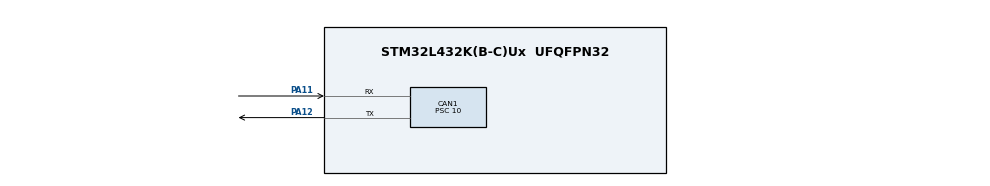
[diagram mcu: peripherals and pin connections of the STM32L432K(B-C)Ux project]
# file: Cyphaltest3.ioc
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CAN1.BS1=CAN_BS1_13TQ
CAN1.BS2=CAN_BS2_2TQ
CAN1.CalculateBaudRate=25000
CAN1.CalculateTimeBit=40000
CAN1.CalculateTimeQuantum=2500.0
CAN1.Prescaler=10
Mcu.Family=STM32L4
Mcu.Name=STM32L432K(B-C)Ux
Mcu.Package=UFQFPN32
NVIC.CAN1_RX0_IRQn=true\:0\:0\:false\:false\:true\:true\:true\:true
NVIC.CAN1_RX1_IRQn=true\:0\:0\:false\:false\:true\:true\:true\:true
NVIC.CAN1_SCE_IRQn=true\:0\:0\:false\:false\:true\:true\:true\:true
NVIC.CAN1_TX_IRQn=true\:0\:0\:false\:false\:true\:true\:true\:true
NVIC.PriorityGroup=NVIC_PRIORITYGROUP_4
PA11.Mode=CAN_Activate
PA11.Signal=CAN1_RX
PA12.Mode=CAN_Activate
PA12.Signal=CAN1_TX
ProjectManager.HeapSize=0x200
ProjectManager.StackSize=0x400
ProjectManager.TargetToolchain=STM32CubeIDE
RCC.HSE_VALUE=8000000
RCC.HSI48_VALUE=48000000
RCC.HSI_VALUE=16000000
RCC.LSE_VALUE=32768
RCC.MSI_VALUE=4000000
RCC.VCOOutputFreq_Value=32000000
board=custom

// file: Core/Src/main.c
/* USER CODE BEGIN Header */
/**
  ******************************************************************************
  * @file           : main.c
  * @brief          : Main program body
  ******************************************************************************
  * @attention
  *
  * Copyright (c) 2025 STMicroelectronics.
  * All rights reserved.
  *
  * This software is licensed under terms that can be found in the LICENSE file
  * in the root directory of this software component.
  * If no LICENSE file comes with this software, it is provided AS-IS.
  *
  ******************************************************************************
  */
/* USER CODE END Header */
#include "main.h"
/* USER CODE BEGIN Includes */
#include <stdlib.h>
#include "libcanard/canard.h"
#include "libcanard/canard.c"
#include "uavcan/node/Heartbeat_1_0.h"
#include "uavcan/node/GetInfo_1_0.h"
#include "uavcan/primitive/array/Real64_1_0.h"
/* USER CODE END Includes */

/* USER CODE BEGIN PD */
#define GETINFO_TARGET_NODE_ID 42
/* USER CODE END PD */

CAN_HandleTypeDef hcan1;

/* USER CODE BEGIN PV */
CanardInstance 	canard;		// This is the core structure that keeps all of the states and allocated resources of the library instance
CanardTxQueue 	queue;		// Prioritized transmission queue that keeps CAN frames destined for transmission via one CAN interface

static uint8_t getinfo_request_transfer_id = 0;
static uint8_t my_message_transfer_id = 0;
CanardPortID const MSG_PORT_ID   = 1620U;
uint32_t test_uptimeSec = 0;

// buffer for serialization of a heartbeat message
size_t hbeat_ser_buf_size = uavcan_node_Heartbeat_1_0_EXTENT_BYTES_;
uint8_t hbeat_ser_buf[uavcan_node_Heartbeat_1_0_EXTENT_BYTES_];
uint8_t getinfo_request_ser_buf[1];
size_t getinfo_request_ser_buf_size = sizeof(getinfo_request_ser_buf);
/* USER CODE END PV */

void SystemClock_Config(void);
static void MX_GPIO_Init(void);
static void MX_CAN1_Init(void);
/* USER CODE BEGIN PFP */
// Wrappers for using o1heap allocator with libcanard
static void* memAllocate(CanardInstance* const ins, const size_t amount);
static void memFree(CanardInstance* const ins, void* const pointer);

// Application-specific function prototypes
void process_canard_TX_queue(void);

// return useconds - not implemented yet
uint32_t micros(void)
{
  return 0;
}
/* USER CODE END PFP */

int main(void)
{

  /* MCU Configuration--------------------------------------------------------*/

  /* Reset of all peripherals, Initializes the Flash interface and the Systick. */
  HAL_Init();

  /* Configure the system clock */
  SystemClock_Config();

  /* Initialize all configured peripherals */
  MX_GPIO_Init();
  MX_CAN1_Init();
  /* USER CODE BEGIN 2 */
  HAL_CAN_Start(&hcan1);
    HAL_CAN_ActivateNotification(&hcan1, CAN_IT_RX_FIFO0_MSG_PENDING);

    CAN_FilterTypeDef Filter;

    // accept all frames - filtration is managed by software
    Filter.FilterIdHigh = 0x0000;
    Filter.FilterIdLow = 0x0000;
    Filter.FilterMaskIdHigh = 0x0000;
    Filter.FilterMaskIdLow = 0x0000;
    Filter.FilterFIFOAssignment = CAN_RX_FIFO0;
    Filter.FilterBank = 0;
    Filter.FilterMode = CAN_FILTERMODE_IDMASK;
    Filter.FilterScale = CAN_FILTERSCALE_32BIT;
    Filter.FilterActivation = ENABLE;
    Filter.SlaveStartFilterBank = 0;

    HAL_CAN_ConfigFilter(&hcan1, &Filter);

    // Initialization of a canard instance with the previous allocator
    canard = canardInit(&memAllocate, &memFree);
    canard.node_id = 96;

    queue = canardTxInit(	100,                 		// Limit the size of the queue at 100 frames.
                          CANARD_MTU_CAN_CLASSIC);

    CanardRxSubscription subscription; // Transfer subscription state.

    if( canardRxSubscribe((CanardInstance *const)&canard,
                          CanardTransferKindMessage,
                          MSG_PORT_ID,
                          uavcan_primitive_array_Real64_1_0_EXTENT_BYTES_,
                          CANARD_DEFAULT_TRANSFER_ID_TIMEOUT_USEC,
                          &subscription) != 1 )
                          {
                            Error_Handler();
                          }
  /* USER CODE END 2 */

  /* Infinite loop */
  /* USER CODE BEGIN WHILE */
  while (1)
  {
	  // Create a heartbeat message
	      uavcan_node_Heartbeat_1_0 test_heartbeat = {.uptime = test_uptimeSec,
	                                                  .health = {uavcan_node_Health_1_0_NOMINAL},
	                                                  .mode = {uavcan_node_Mode_1_0_OPERATIONAL}};

	      // Serialize the heartbeat message
	      if (uavcan_node_Heartbeat_1_0_serialize_(&test_heartbeat, hbeat_ser_buf, &hbeat_ser_buf_size) < 0)
	      {
	        Error_Handler();
	      }

	      // Create a transfer for the heartbeat message
	      const CanardTransferMetadata transfer_metadata = {.priority = CanardPriorityNominal,
	                                                        .transfer_kind = CanardTransferKindMessage,
	                                                        .port_id = uavcan_node_Heartbeat_1_0_FIXED_PORT_ID_,
	                                                        .remote_node_id = CANARD_NODE_ID_UNSET,
	                                                        .transfer_id = my_message_transfer_id,};

	      if(canardTxPush(&queue,               	// Call this once per redundant CAN interface (queue)
	                      &canard,
	                      0,     					// Zero if transmission deadline is not limited.
	                      &transfer_metadata,
	                      hbeat_ser_buf_size,		// Size of the message payload (see Nunavut transpiler)
	                      hbeat_ser_buf) < 0 )
	                      {
	                        Error_Handler();
	                      }
	      // --- Add: Send GetInfo request ---
	      // Example: Send a GetInfo request approximately every 5 seconds
	            if ((test_uptimeSec % 5 == 0) && (test_uptimeSec > 0)) // Avoid sending immediately on startup
	                {
	                    // 1. Create GetInfo request object (content is empty)
	                    uavcan_node_GetInfo_Request_1_0 getinfo_req = {0}; // Initialization to 0 is sufficient

	                    // 2. Serialize the GetInfo request (result size should be 0)
	                    //    Reset the buffer size variable before calling
	                    getinfo_request_ser_buf_size = sizeof(getinfo_request_ser_buf);
	                    int8_t ser_res = uavcan_node_GetInfo_Request_1_0_serialize_(&getinfo_req,
	                                                                                 getinfo_request_ser_buf,
	                                                                                 &getinfo_request_ser_buf_size);
	                    if (ser_res < 0)
	                    {
	                        // Serialization error handling
	                        Error_Handler();
	                    }
	                    // At this point, getinfo_request_ser_buf_size should be equal to 0

	                    // 3. Create transfer metadata for the GetInfo request
	                    const CanardTransferMetadata getinfo_req_metadata = {
	                        .priority       = CanardPriorityNominal,        // Priority of the request
	                        .transfer_kind  = CanardTransferKindRequest,    // <<<--- Key: Set as service request
	                        .port_id        = uavcan_node_GetInfo_1_0_FIXED_PORT_ID_, // Fixed Port ID for GetInfo
	                        .remote_node_id = GETINFO_TARGET_NODE_ID,       // <<<--- Key: Set the target server node ID
	                        .transfer_id    = getinfo_request_transfer_id,  // Use the dedicated transfer ID for GetInfo requests
	                    };

	                    // 4. Push the request into the transmission queue
	                    //    Note: The payload size passed is the actual size after serialization (0)
	                    int32_t push_res = canardTxPush(&queue,
	                                                    &canard,
	                                                    0, // Transmission deadline (0 means unlimited)
	                                                    &getinfo_req_metadata,
	                                                    getinfo_request_ser_buf_size, // <<<--- Pass the actual size after serialization (0)
	                                                    getinfo_request_ser_buf);     // <<<--- Pass the serialization buffer pointer

	                    if (push_res < 0)
	                    {
	                        // Failed to push to queue (e.g., queue is full)
	                        // You can add error handling logic here, e.g., log the error
	                    }
	                    else
	                    {
	                        // After successful push, increment the transfer ID for GetInfo requests
	                        getinfo_request_transfer_id++;
	                    }
	                } // --- End GetInfo request ---
	      // Block for a second before generating the next transfer
	      uint32_t timestamp = HAL_GetTick();
	      while( HAL_GetTick() < timestamp + 1000u )
	      {
	        process_canard_TX_queue();
	        HAL_Delay(10);
	      }

	      // Increase uptime
	      test_uptimeSec++;
	      // Increment the transfer_id variable
	      my_message_transfer_id++;

    /* USER CODE END WHILE */

  }
}

void SystemClock_Config(void)
{
  RCC_OscInitTypeDef RCC_OscInitStruct = {0};
  RCC_ClkInitTypeDef RCC_ClkInitStruct = {0};

  /** Configure the main internal regulator output voltage
  */
  if (HAL_PWREx_ControlVoltageScaling(PWR_REGULATOR_VOLTAGE_SCALE1) != HAL_OK)
  {
    Error_Handler();
  }

  /** Initializes the RCC Oscillators according to the specified parameters
  * in the RCC_OscInitTypeDef structure.
  */
  RCC_OscInitStruct.OscillatorType = RCC_OSCILLATORTYPE_MSI;
  RCC_OscInitStruct.MSIState = RCC_MSI_ON;
  RCC_OscInitStruct.MSICalibrationValue = 0;
  RCC_OscInitStruct.MSIClockRange = RCC_MSIRANGE_6;
  RCC_OscInitStruct.PLL.PLLState = RCC_PLL_NONE;
  if (HAL_RCC_OscConfig(&RCC_OscInitStruct) != HAL_OK)
  {
    Error_Handler();
  }

  /** Initializes the CPU, AHB and APB buses clocks
  */
  RCC_ClkInitStruct.ClockType = RCC_CLOCKTYPE_HCLK|RCC_CLOCKTYPE_SYSCLK
                              |RCC_CLOCKTYPE_PCLK1|RCC_CLOCKTYPE_PCLK2;
  RCC_ClkInitStruct.SYSCLKSource = RCC_SYSCLKSOURCE_MSI;
  RCC_ClkInitStruct.AHBCLKDivider = RCC_SYSCLK_DIV1;
  RCC_ClkInitStruct.APB1CLKDivider = RCC_HCLK_DIV1;
  RCC_ClkInitStruct.APB2CLKDivider = RCC_HCLK_DIV1;

  if (HAL_RCC_ClockConfig(&RCC_ClkInitStruct, FLASH_LATENCY_0) != HAL_OK)
  {
    Error_Handler();
  }
}

static void MX_CAN1_Init(void)
{

  hcan1.Instance = CAN1;
  hcan1.Init.Prescaler = 10;
  hcan1.Init.Mode = CAN_MODE_NORMAL;
  hcan1.Init.SyncJumpWidth = CAN_SJW_1TQ;
  hcan1.Init.TimeSeg1 = CAN_BS1_13TQ;
  hcan1.Init.TimeSeg2 = CAN_BS2_2TQ;
  hcan1.Init.TimeTriggeredMode = DISABLE;
  hcan1.Init.AutoBusOff = DISABLE;
  hcan1.Init.AutoWakeUp = DISABLE;
  hcan1.Init.AutoRetransmission = DISABLE;
  hcan1.Init.ReceiveFifoLocked = DISABLE;
  hcan1.Init.TransmitFifoPriority = DISABLE;
  if (HAL_CAN_Init(&hcan1) != HAL_OK)
  {
    Error_Handler();
  }

}

static void MX_GPIO_Init(void)
{

  /* GPIO Ports Clock Enable */
  __HAL_RCC_GPIOA_CLK_ENABLE();

}

/* USER CODE BEGIN 4 */
void process_canard_TX_queue(void)
{
  // Look at top of the TX queue of individual CAN frames
  for (const CanardTxQueueItem* ti = NULL; (ti = canardTxPeek(&queue)) != NULL;)
  {
    if ((0U == ti->tx_deadline_usec) || (ti->tx_deadline_usec > micros()))  // Check the deadline.
    {
      /* Instantiate a frame for the media layer */
      CAN_TxHeaderTypeDef TxHeader;
      TxHeader.IDE = CAN_ID_EXT;
      TxHeader.RTR = CAN_RTR_DATA;

      TxHeader.DLC = ti->frame.payload_size;
      TxHeader.ExtId = ti->frame.extended_can_id;

      uint8_t TxData[8];
      uint32_t TxMailbox;

      memcpy( TxData, (uint8_t *)ti->frame.payload, ti->frame.payload_size );

      if ( HAL_CAN_AddTxMessage(&hcan1, &TxHeader, TxData, &TxMailbox) != HAL_OK)
      {
        break;
      }
    }
    // After the frame is transmitted or if it has timed out while waiting, pop it from the queue and deallocate:
    canard.memory_free(&canard, canardTxPop(&queue, ti));
  }
}

#pragma optimize=s none
void HAL_CAN_RxFifo0MsgPendingCallback(CAN_HandleTypeDef *hcan)
{
  CAN_RxHeaderTypeDef RxHeader;
  uint8_t RxData[8] = {0};
  uint32_t RxFifo1 = 0;
  HAL_CAN_GetRxMessage(&hcan1, RxFifo1, &RxHeader, RxData);

  CanardFrame rxf;

  rxf.extended_can_id = RxHeader.ExtId;
  rxf.payload_size = (size_t)RxHeader.DLC;
  rxf.payload = (void*)RxData;

  CanardRxTransfer transfer;

  if( canardRxAccept(   (CanardInstance *const)&canard,
                        micros(),
                        &rxf,
                        0,
                        &transfer,
                        NULL) != 1 )
                        {
                          return ; // the frame received is not a valid transfer
                        }

  uavcan_primitive_array_Real64_1_0 array;
  size_t array_ser_buf_size = uavcan_primitive_array_Real64_1_0_EXTENT_BYTES_;

  if ( uavcan_primitive_array_Real64_1_0_deserialize_( &array, transfer.payload, &array_ser_buf_size) < 0)
  {
    Error_Handler();
  }

  canard.memory_free(&canard, transfer.payload);

  HAL_GPIO_TogglePin(GPIOA, GPIO_PIN_5);

  return ;
}

#pragma optimize=s none
void HAL_CAN_RxFifo1MsgPendingCallback(CAN_HandleTypeDef *hcan)
{
  return ;
}

static void* memAllocate(CanardInstance* const ins, const size_t amount)
{
  (void) ins;
  return malloc(amount);
}

static void memFree(CanardInstance* const ins, void* const pointer)
{
  (void) ins;
  free( pointer );
}
/* USER CODE END 4 */

void Error_Handler(void)
{
  __disable_irq();
  while (1)
  {
  }
}
